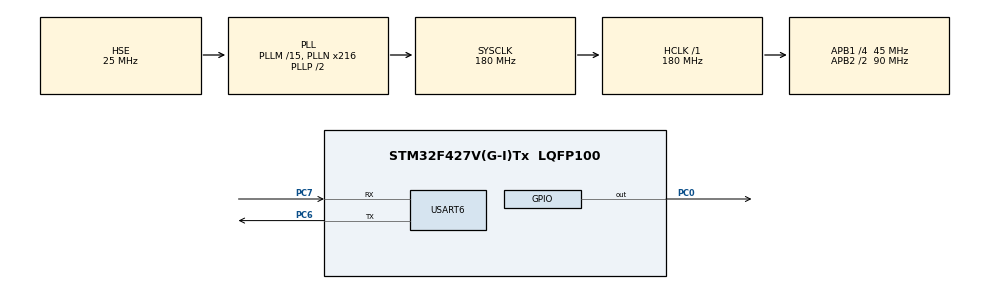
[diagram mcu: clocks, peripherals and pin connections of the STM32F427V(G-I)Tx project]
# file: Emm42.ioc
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Dma.Request0=USART6_RX
Dma.Request1=USART6_TX
Dma.USART6_RX.0.Direction=DMA_PERIPH_TO_MEMORY
Dma.USART6_RX.0.FIFOMode=DMA_FIFOMODE_DISABLE
Dma.USART6_RX.0.Instance=DMA2_Stream1
Dma.USART6_RX.0.MemDataAlignment=DMA_MDATAALIGN_BYTE
Dma.USART6_RX.0.MemInc=DMA_MINC_ENABLE
Dma.USART6_RX.0.Mode=DMA_NORMAL
Dma.USART6_RX.0.PeriphDataAlignment=DMA_PDATAALIGN_BYTE
Dma.USART6_RX.0.PeriphInc=DMA_PINC_DISABLE
Dma.USART6_RX.0.Priority=DMA_PRIORITY_LOW
Dma.USART6_TX.1.Direction=DMA_MEMORY_TO_PERIPH
Dma.USART6_TX.1.FIFOMode=DMA_FIFOMODE_DISABLE
Dma.USART6_TX.1.Instance=DMA2_Stream6
Dma.USART6_TX.1.MemDataAlignment=DMA_MDATAALIGN_BYTE
Dma.USART6_TX.1.MemInc=DMA_MINC_ENABLE
Dma.USART6_TX.1.Mode=DMA_NORMAL
Dma.USART6_TX.1.PeriphDataAlignment=DMA_PDATAALIGN_BYTE
Dma.USART6_TX.1.PeriphInc=DMA_PINC_DISABLE
Dma.USART6_TX.1.Priority=DMA_PRIORITY_LOW
Mcu.Family=STM32F4
Mcu.Name=STM32F427V(G-I)Tx
Mcu.Package=LQFP100
NVIC.DMA2_Stream1_IRQn=true\:0\:0\:false\:false\:true\:false\:true\:true
NVIC.DMA2_Stream6_IRQn=true\:0\:0\:false\:false\:true\:false\:true\:true
NVIC.PriorityGroup=NVIC_PRIORITYGROUP_4
NVIC.TIM6_DAC_IRQn=true\:0\:0\:false\:false\:true\:true\:true\:true
NVIC.USART6_IRQn=true\:0\:0\:false\:false\:true\:true\:true\:true
PA13.Mode=Serial_Wire
PA13.Signal=SYS_JTMS-SWDIO
PA14.Mode=Serial_Wire
PA14.Signal=SYS_JTCK-SWCLK
PC0.Signal=GPIO_Output
PC6.Mode=Asynchronous
PC6.Signal=USART6_TX
PC7.Mode=Asynchronous
PC7.Signal=USART6_RX
PH0/OSC_IN.Mode=HSE-External-Clock-Source
PH0/OSC_IN.Signal=RCC_OSC_IN
PH1/OSC_OUT.Mode=HSE-External-Clock-Source
PH1/OSC_OUT.Signal=RCC_OSC_OUT
ProjectManager.HeapSize=0x200
ProjectManager.StackSize=0x400
ProjectManager.TargetToolchain=Makefile
RCC.48MHZClocksFreq_Value=90000000
RCC.AHBFreq_Value=180000000
RCC.APB1CLKDivider=RCC_HCLK_DIV4
RCC.APB1Freq_Value=45000000
RCC.APB1TimFreq_Value=90000000
RCC.APB2CLKDivider=RCC_HCLK_DIV2
RCC.APB2Freq_Value=90000000
RCC.APB2TimFreq_Value=180000000
RCC.CortexFreq_Value=180000000
RCC.HCLKFreq_Value=180000000
RCC.HSE_VALUE=25000000
RCC.HSI_VALUE=16000000
RCC.LSE_VALUE=32768
RCC.PLLM=15
RCC.PLLN=216
RCC.PLLSourceVirtual=RCC_PLLSOURCE_HSE
RCC.SYSCLKFreq_VALUE=180000000
RCC.SYSCLKSource=RCC_SYSCLKSOURCE_PLLCLK
RCC.VCOOutputFreq_Value=360000000
TIM6.Period=9999
TIM6.Prescaler=89
USART6.VirtualMode=VM_ASYNC
VP_TIM6_VS_ClockSourceINT.Mode=Enable_Timer
board=custom

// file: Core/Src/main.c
/* USER CODE BEGIN Header */
/**
  ******************************************************************************
  * @file           : main.c
  * @brief          : Main program body
  ******************************************************************************
  * @attention
  *
  * Copyright (c) 2026 STMicroelectronics.
  * All rights reserved.
  *
  * This software is licensed under terms that can be found in the LICENSE file
  * in the root directory of this software component.
  * If no LICENSE file comes with this software, it is provided AS-IS.
  *
  ******************************************************************************
  */
/* USER CODE END Header */
#include "main.h"
#include "dma.h"
#include "tim.h"
#include "usart.h"
#include "gpio.h"

/* USER CODE BEGIN Includes */
#include "Emm_V5.h"
#include "stdbool.h"
/* USER CODE END Includes */

void SystemClock_Config(void);

int main(void)
{

  /* MCU Configuration--------------------------------------------------------*/

  /* Reset of all peripherals, Initializes the Flash interface and the Systick. */
  HAL_Init();

  /* Configure the system clock */
  SystemClock_Config();

  /* Initialize all configured peripherals */
  MX_GPIO_Init();
  MX_DMA_Init();
  MX_USART6_UART_Init();
  MX_TIM6_Init();
  /* USER CODE BEGIN 2 */

  HAL_TIM_Base_Start_IT(&htim6);

  // 纯串口发送测试
  // uint8_t test_init[] = {0x01, 0xF3, 0xAB, 0x01, 0x00, 0x6B};
  // uint8_t test_move[] = {0x01, 0xF6, 0x00, 0x05, 0xDC, 0x00, 0x00, 0x6B};
  // HAL_UART_Transmit_DMA(&huart6, test_init, sizeof(test_init));

  HAL_Delay(1000); //延时等待电机开机

  // 电机使能（不同步）
  // Emm_V5_En_Control(0x01, true, false);
  // HAL_Delay(10);
  // Emm_V5_En_Control(0x02, true, false);
  // HAL_Delay(10);

  // 电机使能（同步）
  Emm_V5_En_Control(0x01, true, true);
  HAL_Delay(10);
  Emm_V5_En_Control(0x02, true, true);
  HAL_Delay(10);

  /**
  * 二维云台
  * 齿轮：大（100），中（50）， 小（10）
  * 0x01为10:1，0x02为5:1
  * 对0x01，0x00为顺时针（俯视）；对0x02，0x01为逆时针，表现为向下运动
  * 位置模式：3200为一圈
  */

  Emm_V5_Pos_Control(0x02, 0x00, 2000, 200, 3200*1, 0x00, true); //顺时针
  HAL_Delay(10);
  Emm_V5_Pos_Control(0x01, 0x01, 2000, 200, 3200*0.5, 0x00, true); // 逆时针，向下
  HAL_Delay(10);
  Emm_V5_Synchronous_motion(0x00);
  // Motor_Vel_Linear_Acc(0x01, 0x01, 4000, 0x00, 100);
  // Motor_Linear_Acc(0x01, 0x01, 1000, 0x00, 3200*10, 100);
  // HAL_Delay(3000);
  // Emm_V5_Stop_Now(0x01, false);

  /* USER CODE END 2 */

  /* Infinite loop */
  while (1)
  {

    /* USER CODE BEGIN 3 */

    // 串口发送测试
    // HAL_UART_Transmit_DMA(&huart6, test_move, sizeof(test_move));

    // 每10s改变状态（同转同停）
    // if(flag == 0)
    // {
    //   Emm_V5_Vel_Control(0x01, 0x00, 500, 0x00, true);
    //   HAL_Delay(10);
    //   Emm_V5_Vel_Control(0x02, 0x00, 100, 0x00, true);
    //   HAL_Delay(10);
    //   Emm_V5_Synchronous_motion(0x00);
    //   HAL_Delay(10);
    // }
    // else
    // {
    //   Emm_V5_Stop_Now(0x01, true);
    //   HAL_Delay(10);
    //   Emm_V5_Stop_Now(0x02, true);
    //   HAL_Delay(10);
    //   Emm_V5_Synchronous_motion(0x00);
    //   HAL_Delay(10);
    // }

    // 每10s改变状态（一停一转）
    // if (flag == 0)
    // {
    //   Emm_V5_Vel_Control(0x01, 0x00, 500, 0x00, false);
    //   HAL_Delay(10);
    //   Emm_V5_Stop_Now(0x02, false);
    //   HAL_Delay(10);
    // }
    // else
    // {
    //   Emm_V5_Vel_Control(0x02, 0x00, 500, 0x00, false);
    //   HAL_Delay(10);
    //   Emm_V5_Stop_Now(0x01, false);
    //   HAL_Delay(10);
    // }

    // Emm_V5_Pos_Control(0x01, 0x01, 500, 0x00, 3200, 0x00, false);

    HAL_GPIO_TogglePin(GPIOC, GPIO_PIN_0);
    HAL_Delay(100);
  }
  /* USER CODE END 3 */
}

void SystemClock_Config(void)
{
  RCC_OscInitTypeDef RCC_OscInitStruct = {0};
  RCC_ClkInitTypeDef RCC_ClkInitStruct = {0};

  /** Configure the main internal regulator output voltage
  */
  __HAL_RCC_PWR_CLK_ENABLE();
  __HAL_PWR_VOLTAGESCALING_CONFIG(PWR_REGULATOR_VOLTAGE_SCALE1);

  /** Initializes the RCC Oscillators according to the specified parameters
  * in the RCC_OscInitTypeDef structure.
  */
  RCC_OscInitStruct.OscillatorType = RCC_OSCILLATORTYPE_HSE;
  RCC_OscInitStruct.HSEState = RCC_HSE_BYPASS;
  RCC_OscInitStruct.PLL.PLLState = RCC_PLL_ON;
  RCC_OscInitStruct.PLL.PLLSource = RCC_PLLSOURCE_HSE;
  RCC_OscInitStruct.PLL.PLLM = 15;
  RCC_OscInitStruct.PLL.PLLN = 216;
  RCC_OscInitStruct.PLL.PLLP = RCC_PLLP_DIV2;
  RCC_OscInitStruct.PLL.PLLQ = 4;
  if (HAL_RCC_OscConfig(&RCC_OscInitStruct) != HAL_OK)
  {
    Error_Handler();
  }

  /** Activate the Over-Drive mode
  */
  if (HAL_PWREx_EnableOverDrive() != HAL_OK)
  {
    Error_Handler();
  }

  /** Initializes the CPU, AHB and APB buses clocks
  */
  RCC_ClkInitStruct.ClockType = RCC_CLOCKTYPE_HCLK|RCC_CLOCKTYPE_SYSCLK
                              |RCC_CLOCKTYPE_PCLK1|RCC_CLOCKTYPE_PCLK2;
  RCC_ClkInitStruct.SYSCLKSource = RCC_SYSCLKSOURCE_PLLCLK;
  RCC_ClkInitStruct.AHBCLKDivider = RCC_SYSCLK_DIV1;
  RCC_ClkInitStruct.APB1CLKDivider = RCC_HCLK_DIV4;
  RCC_ClkInitStruct.APB2CLKDivider = RCC_HCLK_DIV2;

  if (HAL_RCC_ClockConfig(&RCC_ClkInitStruct, FLASH_LATENCY_5) != HAL_OK)
  {
    Error_Handler();
  }
}

void Error_Handler(void)
{
  __disable_irq();
  while (1)
  {
  }
}
